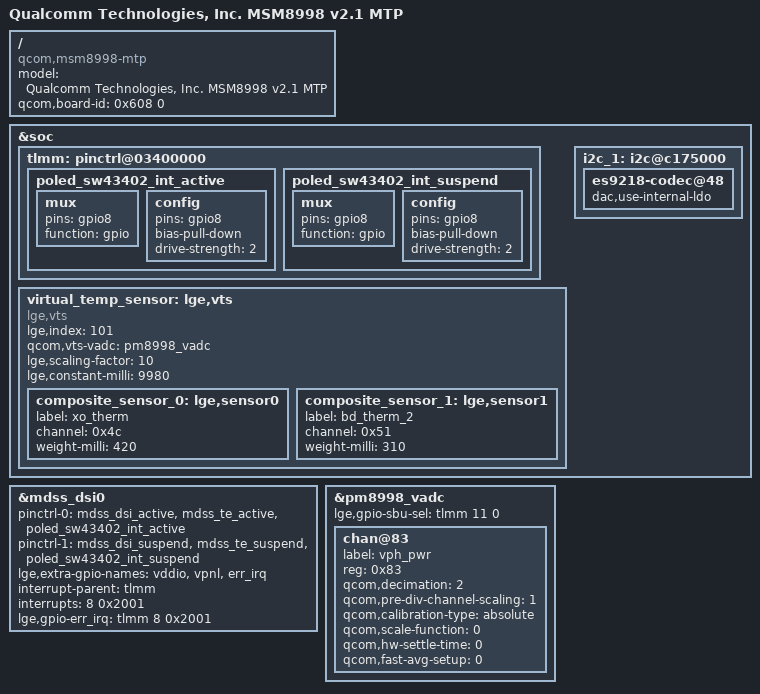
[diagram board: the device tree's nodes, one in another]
/* Copyright (c) 2016, The Linux Foundation. All rights reserved.
 *
 * This program is free software; you can redistribute it and/or modify
 * it under the terms of the GNU General Public License version 2 and
 * only version 2 as published by the Free Software Foundation.
 *
 * This program is distributed in the hope that it will be useful,
 * but WITHOUT ANY WARRANTY; without even the implied warranty of
 * MERCHANTABILITY or FITNESS FOR A PARTICULAR PURPOSE.  See the
 * GNU General Public License for more details.
 */


/dts-v1/;

#include "../../../qcom/msm8998-v2.1.dtsi"
#include "msm8998-joan_global_ca.dtsi"

/ {
	model = "Qualcomm Technologies, Inc. MSM8998 v2.1 MTP";
	compatible = "qcom,msm8998-mtp", "qcom,msm8998", "qcom,mtp";
	qcom,board-id = <0x608 0>;
};

&soc {
	tlmm: pinctrl@03400000 {
		poled_sw43402_int_active:poled_sw43402_int_active {
			mux {
				pins = "gpio8";
				function = "gpio";
			};

			config {
				pins = "gpio8";
				bias-pull-down;
				drive-strength = <2>; /* 2 MA */
			};
		};
		poled_sw43402_int_suspend:poled_sw43402_int_suspend {
			mux {
				pins = "gpio8";
				function = "gpio";
			};
			config {
				pins = "gpio8";
				bias-pull-down;
				drive-strength = <2>; /* 2 MA */
			};
		};
	};

	/* TODO : tune, vts, 0.42*XO + 0.31*Bd2 + 9.98 */
	virtual_temp_sensor: lge,vts {
		compatible = "lge,vts";
		lge,index = <101>;
		qcom,vts-vadc = <&pm8998_vadc>;
		lge,scaling-factor = <10>;
		lge,constant-milli = <9980>;

		composite_sensor_0: lge,sensor0 {
			label = "xo_therm";
			channel = <0x4c>;
			weight-milli = <420>;
		};

		composite_sensor_1: lge,sensor1 {
			label = "bd_therm_2";
			channel = <0x51>;
			weight-milli = <310>;
		};
	};
};
&mdss_dsi0 {

	pinctrl-names = "mdss_default", "mdss_sleep";
	pinctrl-0 = <&mdss_dsi_active &mdss_te_active &poled_sw43402_int_active>;
	pinctrl-1 = <&mdss_dsi_suspend &mdss_te_suspend &poled_sw43402_int_suspend>;

	lge,extra-gpio-names = "vddio", "vpnl", "err_irq";

	interrupt-parent = <&tlmm>;
	interrupts = <8 0x2001>; /*IRQF_ONESHOT | IRQF_TRIGGER_RISING*/
	lge,gpio-err_irq =  <&tlmm 8 0x2001>; /* IRQF_ONESHOT | IRQF_TRIGGER_RISING */
};

&pm8998_vadc {
	lge,gpio-sbu-sel = <&tlmm 11 0>;
	chan@83 {
		label = "vph_pwr";
		reg = <0x83>;
		qcom,decimation = <2>;
		qcom,pre-div-channel-scaling = <1>;
		qcom,calibration-type = "absolute";
		qcom,scale-function = <0>;
		qcom,hw-settle-time = <0>;
		qcom,fast-avg-setup = <0>;
    };
};

&soc {
    i2c_1: i2c@c175000 {
        es9218-codec@48 {
            dac,use-internal-ldo;
        };
    };
};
